# haltium_flpr register map
Vendor: Nordic Semiconductor; Series: nRFHaltium; File version: 1
Registers are 32-bit, read-write, reset 0x0 unless marked. A register's access mark holds for its fields unless they carry their own. Offsets are from the block's base; [hi:lo] are bit positions; lines under a group give offsets from that group; {n}, {i} and the like mark numbered series; 'fields as' and 'values as' point back to an identical list.

## GLOBAL_GMUTEX0_NS — MUTEX 0
Base 0x4F8D2000
Same registers: GLOBAL_GMUTEX1_NS 0x4F927000
{0x400+4i} MUTEX[{i}] (i=0..15) — Description collection: Mutex register
  [0] MUTEX — Mutex register n
    0=Unlocked (Mutex n is in unlocked state); 1=Locked (Mutex n is in locked state)

## GLOBAL_I3C0_NS — I3C 0
Base 0x4F8D3000
Same registers: GLOBAL_I3C1_NS 0x4F8D4000, GLOBAL_I3C2_NS 0x4F8D5000, GLOBAL_I3C3_NS 0x4F8D6000, GLOBAL_I3C0_S 0x5F8D3000, GLOBAL_I3C1_S 0x5F8D4000, GLOBAL_I3C2_S 0x5F8D5000, GLOBAL_I3C3_S 0x5F8D6000
0x100 EVENTS_CORE — Event indicating that interrupt triggered at I3C core
  [0] EVENTS_CORE
    0=NotGenerated (Event not generated); 1=Generated (Event generated)
0x104 EVENTS_DMA — Event indicating that interrupt triggered at I3C DMA
  [0] EVENTS_DMA
    values as EVENTS_CORE.EVENTS_CORE
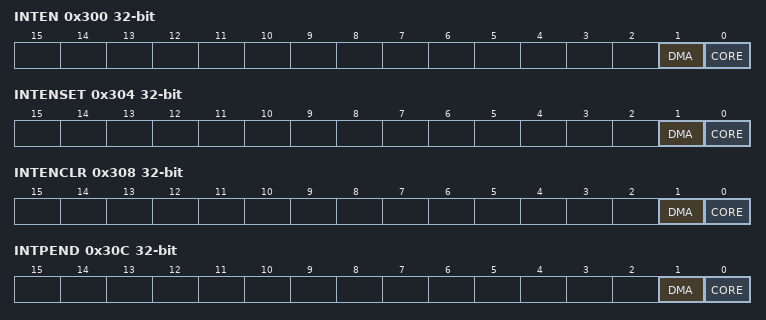
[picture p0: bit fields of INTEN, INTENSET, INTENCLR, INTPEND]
0x300 INTEN — Enable or disable interrupt
  [1] DMA — Enable or disable interrupt for event DMA
    0=Disabled; 1=Enabled
  [0] CORE — Enable or disable interrupt for event CORE
    0=Disabled; 1=Enabled
0x304 INTENSET — Enable interrupt
  [1] DMA — Write '1' to enable interrupt for event DMA
    on read: 0=Disabled (Read: Disabled); 1=Enabled (Read: Enabled) | on write: 1=Set (Enable)
  [0] CORE — Write '1' to enable interrupt for event CORE
    values as DMA
0x308 INTENCLR — Disable interrupt
  [1] DMA — Write '1' to disable interrupt for event DMA
    on read: 0=Disabled (Read: Disabled); 1=Enabled (Read: Enabled) | on write: 1=Clear (Disable)
  [0] CORE — Write '1' to disable interrupt for event CORE
    values as DMA
0x30C INTPEND ro — Pending interrupts
  [1] DMA — Read pending status of interrupt for event DMA
    on read: 0=NotPending (Read: Not pending); 1=Pending (Read: Pending)
  [0] CORE — Read pending status of interrupt for event CORE
    values as DMA
0x400 ENABLE — Enable I3C peripheral.
  [0] EN — Enable
    0=Disabled (I3C peripheral disabled.); 1=Enabled (I3C peripheral enabled.)
0x404 CDR group — Unspecified
  0x00 STARTOFFSET — Start offset of recovered clock
    [15:0] VAL — Value
  0x04 MAXCYCLERATIO — Maximum cycle ratio between SDA/SCL and CDR (clock and data recovery) clock
    [15:0] VAL — Value
  0x08 MAXSKEW — Maximum skew between SCL and SCL in CDR clock cycles
    [7:0] VAL — Value
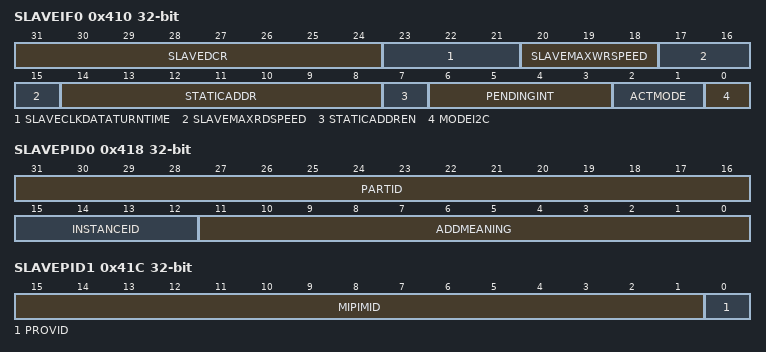
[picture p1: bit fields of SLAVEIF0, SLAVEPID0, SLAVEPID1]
0x410 SLAVEIF0 — I3C slave interface 0
  [31:24] SLAVEDCR — Device Characteristic Register value
  [23:21] SLAVECLKDATATURNTIME — Slave maximum clock data turnaround time
  [20:18] SLAVEMAXWRSPEED — Slave maximum write write rate
  [17:15] SLAVEMAXRDSPEED — Slave maximum read data rate
  [14:8] STATICADDR — Slave static address
  [7] STATICADDREN — Slave static address valid
    0=DISABLED (Unspecified); 1=ENABLED (Unspecified)
  [6:3] PENDINGINT — Pending interrupt information for GETSTATUS CCC
  [2:1] ACTMODE — Slave activity mode for GETSTATUS CCC
  [0] MODEI2C — I2C or I3C mode select signal
    0=DISABLED (Unspecified); 1=ENABLED (Unspecified)
0x414 SLAVEIF1 — I3C slave interface 1
  [0] WAKEUP — Slave wakeup signal
    0=DISABLED (Unspecified); 1=ENABLED (Unspecified)
0x418 SLAVEPID0 — Slave Device Provisioned ID 0
  [31:16] PARTID
  [15:12] INSTANCEID
  [11:0] ADDMEANING — Additional Meaning
0x41C SLAVEPID1 — Slave Device Provisioned ID 1
  [15:1] MIPIMID — MIPI Manufacturer ID
  [0] PROVID — Provisional ID Type Selector

## CLIC_NS — Core-Local Interrupt Controller 0
Base 0x4F8D8000
Same registers: CLIC_S 0x5F8D8000
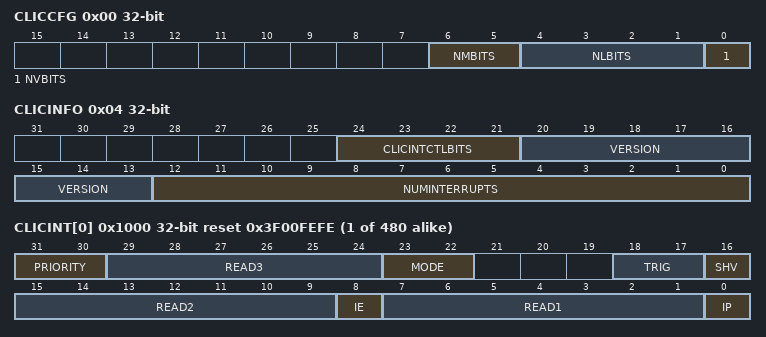
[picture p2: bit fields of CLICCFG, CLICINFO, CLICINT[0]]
0x00 CLICCFG ro — CLIC configuration.
  [6:5] NMBITS — Interrupt previlage mode.
    0=ModeM (All interrupts are M-mode only); 1=ModeS (Interrupts can be S-mode); 2=ModeSU (Interrupts can be S-mode or U-mode)
  [4:1] NLBITS — Interrupt level encoding.
  [0] NVBITS — Selective interrupt hardware vectoring.
    0=NotImplemented (Selective interrupt hardware vectoring is not implemented); 1=Implemented (Selective interrupt hardware vectoring is implemented)
0x04 CLICINFO ro — CLIC information.
  [24:21] CLICINTCTLBITS — Implemented bit in the CLICINT.CTL register.
  [20:13] VERSION
  [12:0] NUMINTERRUPTS — Maximum number of interrupts supported.
{0x1000+4i} CLICINT[{i}] (i=0..479) reset 0x3F00FEFE — Description collection: Interrupt control register for IRQ number [n].
  [31:30] PRIORITY — Interrupt priority.
  [29:24] READ3 ro — Read as 1, write ignored.
  [23:22] MODE ro — Privilege mode.
    0=UserMode; 1=SupervisorMode; 3=MachineMode
  [18:17] TRIG ro — Trigger type and polarity for each interrupt input.
    0=EdgeTriggered (Interrupts are edge-triggered); 1=LevelTriggered (Interrupts are level-triggered); 2=NegativeEdge (Interrupts are positive edge-triggered); 3=PositiveEdge (Interrupts are positive level-triggered)
  [16] SHV ro — Selective Hardware Vectoring.
    0=NonVectored (Interrupt to be non-vectored); 1=Vectored (Hardware vectored)
  [15:9] READ2 ro — Read as 1, write ignored.
  [8] IE — Interrupt enable bit.
    0=Disabled (Interrupt disabled); 1=Enabled (Interrupt enabled)
  [7:1] READ1 ro — Read as 1, write ignored.
  [0] IP — Interrupt Pending bit.
    0=NotPending (Interrupt not pending); 1=Pending (Interrupt pending)
